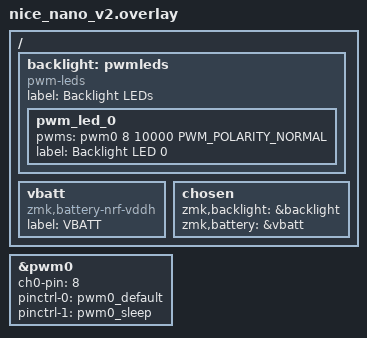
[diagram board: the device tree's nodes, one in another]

&pwm0 {
    status = "okay";
    ch0-pin = <8>;
    /* ch0-inverted; */
    pinctrl-0 = <&pwm0_default>;
    pinctrl-1 = <&pwm0_sleep>;
    pinctrl-names = "default", "sleep";
};

/ {
    backlight: pwmleds {
        compatible = "pwm-leds";
        label = "Backlight LEDs";
        pwm_led_0 {
            pwms = <&pwm0 8 10000 PWM_POLARITY_NORMAL>;
            label = "Backlight LED 0";
        };
    };

    vbatt: vbatt {
        compatible = "zmk,battery-nrf-vddh";
        label = "VBATT";
    };

    chosen {
        zmk,backlight = &backlight;
        zmk,battery = &vbatt;
    };
};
